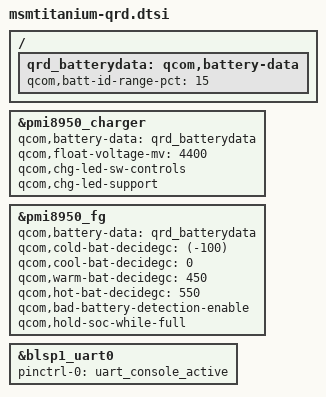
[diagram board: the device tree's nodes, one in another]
/*
 * Copyright (c) 2015, The Linux Foundation. All rights reserved.
 *
 * This program is free software; you can redistribute it and/or modify
 * it under the terms of the GNU General Public License version 2 and
 * only version 2 as published by the Free Software Foundation.
 *
 * This program is distributed in the hope that it will be useful,
 * but WITHOUT ANY WARRANTY; without even the implied warranty of
 * MERCHANTABILITY or FITNESS FOR A PARTICULAR PURPOSE.  See the
 * GNU General Public License for more details.
 */

#include "msmtitanium-pinctrl.dtsi"

/ {
	qrd_batterydata: qcom,battery-data {
		qcom,batt-id-range-pct = <15>;
		#include "batterydata-qrd-sku1-4v4-2800mah.dtsi"
	};
};

&pmi8950_charger {
	qcom,battery-data = <&qrd_batterydata>;
	qcom,float-voltage-mv = <4400>;
	qcom,chg-led-sw-controls;
	qcom,chg-led-support;
	status = "okay";
};

&pmi8950_fg {
	qcom,battery-data = <&qrd_batterydata>;
	qcom,cold-bat-decidegc = <(-100)>;
	qcom,cool-bat-decidegc = <0>;
	qcom,warm-bat-decidegc = <450>;
	qcom,hot-bat-decidegc = <550>;
	qcom,bad-battery-detection-enable;
	qcom,hold-soc-while-full;
};

&blsp1_uart0 {
	status = "ok";
	pinctrl-names = "default";
	pinctrl-0 = <&uart_console_active>;
};
